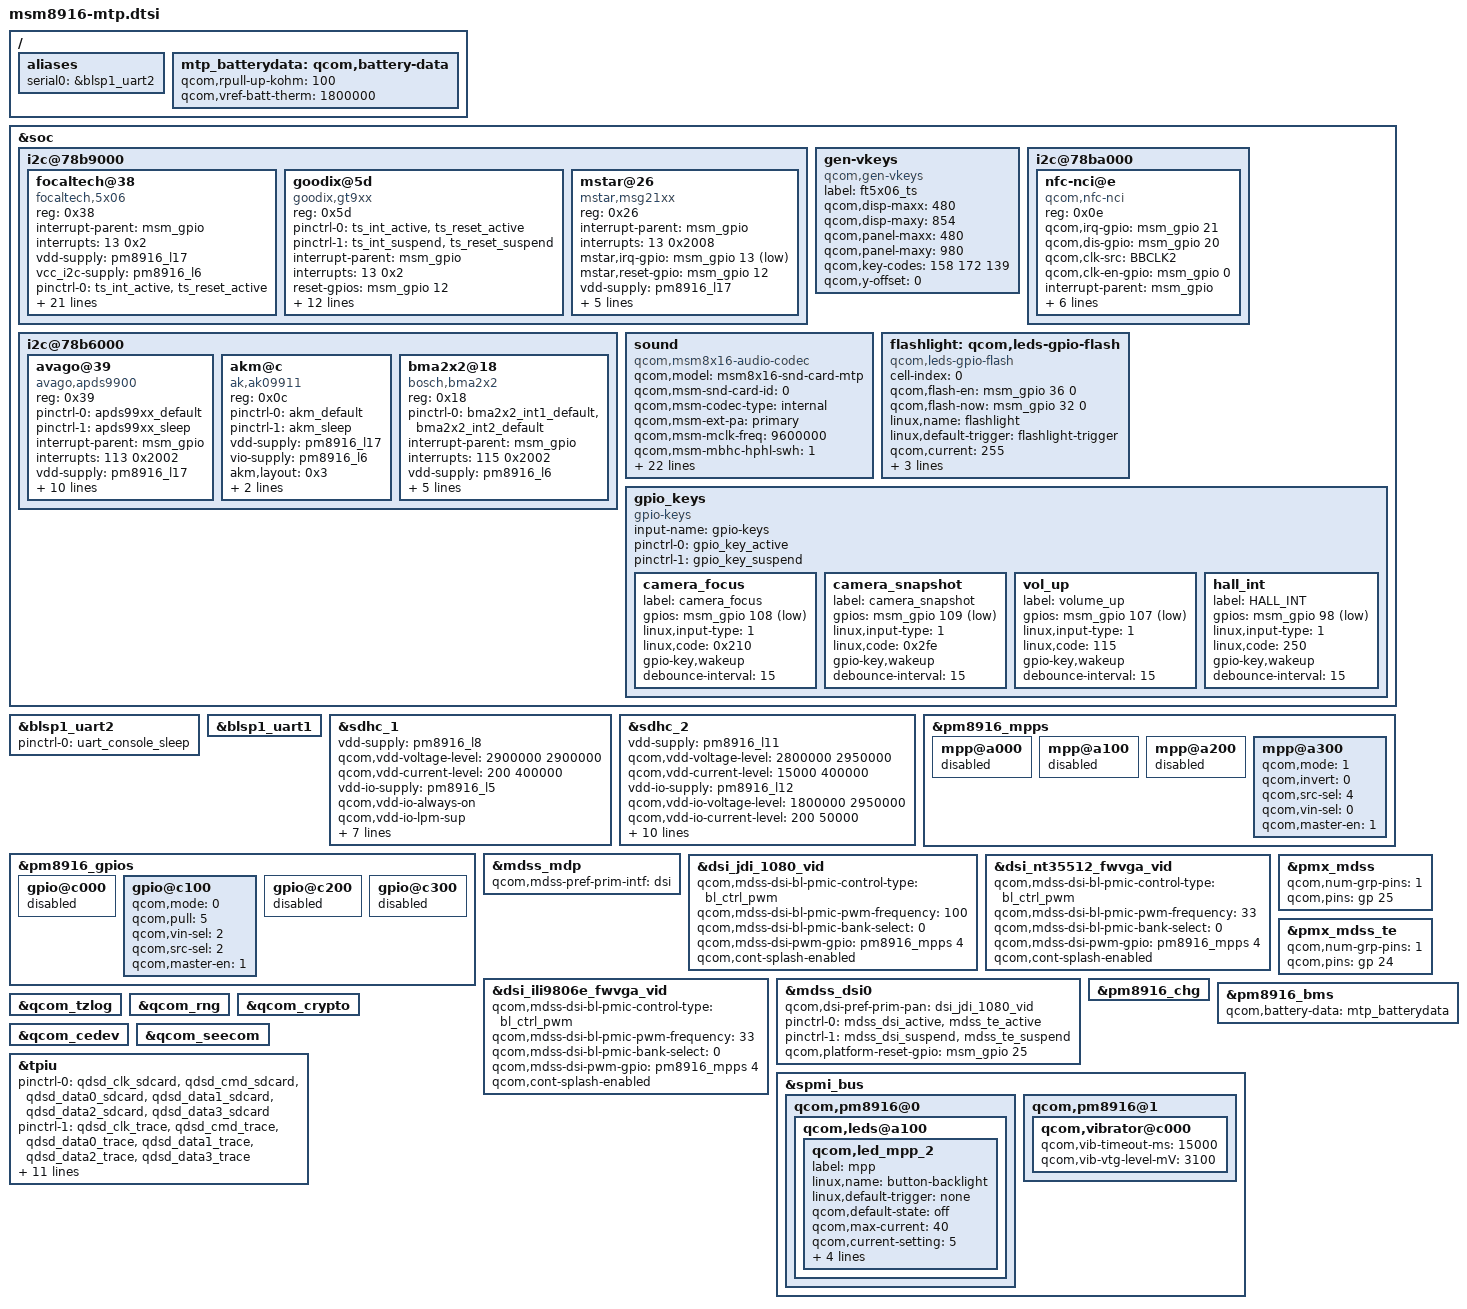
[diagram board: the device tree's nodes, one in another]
/* Copyright (c) 2014, The Linux Foundation. All rights reserved.
 *
 * This program is free software; you can redistribute it and/or modify
 * it under the terms of the GNU General Public License version 2 and
 * only version 2 as published by the Free Software Foundation.
 *
 * This program is distributed in the hope that it will be useful,
 * but WITHOUT ANY WARRANTY; without even the implied warranty of
 * MERCHANTABILITY or FITNESS FOR A PARTICULAR PURPOSE.  See the
 * GNU General Public License for more details.
 */

#include "msm8916.dtsi"
#include "msm8916-pinctrl.dtsi"
#include "msm8916-camera-sensor-mtp.dtsi"

/ {
	aliases {
		serial0 = &blsp1_uart2;
	};
};

&soc {

/*[PLATFORM]-MOD BGEIN by TCTNB.YJ, 2014/03/25, add tp driver */
	i2c@78b9000 { /* BLSP1 QUP5 */
		focaltech@38{
			compatible = "focaltech,5x06";
			reg = <0x38>;
			interrupt-parent = <&msm_gpio>;
			interrupts = <13 0x2>;
			vdd-supply = <&pm8916_l17>;
			vcc_i2c-supply = <&pm8916_l6>;
			/* pins used by touchscreen */
			pinctrl-names = "pmx_ts_active","pmx_ts_suspend";
			pinctrl-0 = <&ts_int_active &ts_reset_active>;
			pinctrl-1 = <&ts_int_suspend &ts_reset_suspend>;
			focaltech,name = "ft6x06";
			focaltech,family-id = <0x06>;
			focaltech,reset-gpio = <&msm_gpio 12 0x00>;
			focaltech,irq-gpio = <&msm_gpio 13 0x00>;
			focaltech,display-coords = <0 0 480 854>;
			focaltech,panel-coords = <0 0 480 980>;
			focaltech,button-map= <139 102 158>;
			focaltech,no-force-update;
			focaltech,i2c-pull-up;
			focaltech,group-id = <1>;
			focaltech,hard-reset-delay-ms = <20>;
			focaltech,soft-reset-delay-ms = <150>;
			focaltech,num-max-touches = <2>;
//                      focaltech,fw-name = "ft_8610_qrd_fw.bin";
			focaltech,fw-delay-aa-ms = <100>;
			focaltech,fw-delay-55-ms = <30>;
			focaltech,fw-upgrade-id1 = <0x79>;
			focaltech,fw-upgrade-id2 = <0x08>;
			focaltech,fw-delay-readid-ms = <10>;
			focaltech,fw-delay-era-flsh-ms = <2000>;
//                      focaltech,fw-auto-cal;
			focaltech,ignore-id-check;
		};
               goodix@5d {
                       compatible = "goodix,gt9xx";
                       reg = <0x5d>;
			/* pins used by touchscreen */
			pinctrl-names = "pmx_ts_active","pmx_ts_suspend";
			pinctrl-0 = <&ts_int_active &ts_reset_active>;
			pinctrl-1 = <&ts_int_suspend &ts_reset_suspend>;

			interrupt-parent = <&msm_gpio>;
			interrupts = <13 0x2>;
			reset-gpios = <&msm_gpio 12 0x00>;
			interrupt-gpios = <&msm_gpio 13 0x00>;

			vdd-supply = <&pm8916_l17>;
			vcc_i2c-supply = <&pm8916_l6>;

			goodix,panel-coords = <0 0 480 854>;
			goodix,display-coords = <0 0 480 980>;
			goodix,button-map= <158 172 139>;
			goodix,product-id = "950";
			goodix,force-update;
			goodix,enable-power-off;
/*                      goodix,cfg-data0 = [
                                46 1C 02 C0 03 0A 05 11 01 08
                                14 3B 46 32 03 05 00 00 00 00
                                00 00 00 00 00 00 00 8A 09 0B
                                39 00 99 0A 00 00 02 83 03 1D
                                00 08 00 00 00 00 00 00 00 00
                                00 1D 73 94 C5 02 07 00 00 04
                                78 21 00 5C 2C 00 48 3A 00 3A
                                4C 00 2F 65 00 30 10 30 50 00
                                56 45 35 FF FF 17 00 00 00 00
                                00 01 1C 15 0C 14 5F 03 02 00
                                00 00 00 00 00 00 00 00 00 00
                                00 00 16 14 12 10 0E 0C 0A 08
                                06 04 02 FF FF FF 00 00 00 00
                                00 00 00 00 00 00 00 00 00 00
                                00 00 22 21 20 1F 1E 1D 1C 18
                                16 12 10 0F 0C 0A 08 06 04 02
                                00 FF FF FF FF FF FF FF 00 00
                                00 FF FF FF FF FF FF FF FF FF
                                F8 FF FF FF E4 01];
*/
//                      goodix,have-touch-key;
			goodix,driver-send-cfg;
			/* Underlying clocks used by secure touch */
			clocks = <&clock_gcc clk_gcc_blsp1_ahb_clk>,
			 <&clock_gcc clk_gcc_blsp1_qup5_i2c_apps_clk>;
			clock-names = "iface_clk", "core_clk";
		};
               mstar@26 {
                       compatible = "mstar,msg21xx";
                       reg = <0x26>;
                       interrupt-parent = <&msm_gpio>;
                       interrupts = <13 0x2008>;
                       mstar,irq-gpio = <&msm_gpio 13 0x00000001>;
                       mstar,reset-gpio = <&msm_gpio 12 0x0>;
                       vdd-supply = <&pm8916_l17>;
                       vcc_i2c-supply = <&pm8916_l6>;
                       mstar,display-coords = <0 0 480 854>;
                       pinctrl-names = "pmx_ts_active","pmx_ts_suspend";
                       pinctrl-0 = <&ts_int_active &ts_reset_active>;
                       pinctrl-1 = <&ts_int_suspend &ts_reset_suspend>;
                       mstar,button-map= <139 172 158>;
               };
	};

	gen-vkeys {
		compatible = "qcom,gen-vkeys";
		label = "ft5x06_ts";
		qcom,disp-maxx = <480>;
		qcom,disp-maxy = <854>;
		qcom,panel-maxx = <480>;
		qcom,panel-maxy = <980>;
		qcom,key-codes = <158 172 139>;
		qcom,y-offset = <0>;
	};
/*[PLATFORM]-END by TCTNB.YJ*/

	i2c@78ba000 { /* BLSP1 QUP6 */
		nfc-nci@e {
			compatible = "qcom,nfc-nci";
			reg = <0x0e>;
			qcom,irq-gpio = <&msm_gpio 21 0x00>;
			qcom,dis-gpio = <&msm_gpio 20 0x00>;
			qcom,clk-src = "BBCLK2";
			qcom,clk-en-gpio = <&msm_gpio 0 0x00>;
			interrupt-parent = <&msm_gpio>;
			interrupts = <21 0>;
			interrupt-names = "nfc_irq";
			pinctrl-names = "nfc_active","nfc_suspend";
			pinctrl-0 = <&nfc_int_active &nfc_disable_active>;
			pinctrl-1 = <&nfc_int_suspend &nfc_disable_suspend>;
			qcom,clk-gpio = <&pm8916_gpios 2 0>;
			clocks = <&clock_rpm clk_bb_clk2_pin>;
			clock-names = "ref_clk";
		};
	};

	i2c@78b6000 { /* BLSP1 QUP2 */
/*[PLATFORM]-Mod-BGEIN by TCTNB.XQJ,2014/08/014, bug 758901,758937 add sensors */
	avago@39 { /* Ambient light and proximity sensor */
		compatible = "avago,apds9900";
		reg = <0x39>;
		pinctrl-names = "default","sleep";
		pinctrl-0 = <&apds99xx_default>;
		pinctrl-1 = <&apds99xx_sleep>;
		interrupt-parent = <&msm_gpio>;
		interrupts = <113 0x2002>;
		vdd-supply = <&pm8916_l17>;
		vio-supply = <&pm8916_l6>;
		avago,irq-gpio = <&msm_gpio 113 0x2002>;
		avago,ps-threshold = <600>;
		avago,ps-hysteresis-threshold = <500>;
		avago,ps-pulse = <20>;
		avago,ps-pgain = <4>;
		avago,als-B = <223>;
		avago,als-C = <70>;
		avago,als-D = <142>;
		avago,ga-value = <48>;
	};

	akm@c {
		compatible = "ak,ak09911";
		reg = <0x0c>;
		pinctrl-names = "default","sleep";
		pinctrl-0 = <&akm_default>;
		pinctrl-1 = <&akm_sleep>;
		vdd-supply = <&pm8916_l17>;
		vio-supply = <&pm8916_l6>;
		akm,layout = <0x3>;
		akm,gpio_rstn = <&msm_gpio 8 0x0>;
		akm,auto-report;
	};

	bma2x2@18 { /* Accelerometer sensor */
		compatible = "bosch,bma2x2";
		reg = <0x18>;
		pinctrl-names = "default";
		pinctrl-0 = <&bma2x2_int1_default &bma2x2_int2_default>;
		interrupt-parent = <&msm_gpio>;
		interrupts = <115 0x2002>;
		vdd-supply = <&pm8916_l6>;
		vio-supply = <&pm8916_l6>;
		bosch,init-interval = <200>;
		bosch,place = <2>;
		bosch,gpio-int1 = <&msm_gpio 115 0x2002>;
		bosch,gpio-int2 = <&msm_gpio 114 0x2002>;
	};

};
/*[PLATFORM]-End by TCTNB.XQJ*/
	sound {
		compatible = "qcom,msm8x16-audio-codec";
		qcom,model = "msm8x16-snd-card-mtp";
		qcom,msm-snd-card-id = <0>;
		qcom,msm-codec-type = "internal";
		qcom,msm-ext-pa = "primary";
		qcom,msm-mclk-freq = <9600000>;
/* [PLATFORM]-Mod-BEGIN by TCTNB.THW, 2014/08/21*/
		qcom,msm-mbhc-hphl-swh = <1>;
/* [PLATFORM]-Mod-END by TCTNB.THW, 2014/08/21*/
		qcom,msm-mbhc-gnd-swh = <0>;
		qcom,msm-micbias1-ext-cap;
		qcom,msm-hs-micbias-type = "internal";
		qcom,audio-routing =
			"RX_BIAS", "MCLK",
			"SPK_RX_BIAS", "MCLK",
			"INT_LDO_H", "MCLK",
/* [PLATFORM]-Mod-BEGIN by TCTNB.THW, 2014/08/21*/
			"MIC BIAS Internal1", "Handset Mic",
			"MIC BIAS Internal2", "Headset Mic",
			"MIC BIAS Internal3", "Secondary Mic",
			"AMIC1", "MIC BIAS Internal1",
			"AMIC2", "MIC BIAS Internal2",
			"AMIC3", "MIC BIAS Internal3",
/* [PLATFORM]-Mod-END by TCTNB.THW, 2014/08/21*/
			"DMIC1", "MIC BIAS Internal1",
			"MIC BIAS Internal1", "Digital Mic1",
			"DMIC2", "MIC BIAS Internal1",
			"MIC BIAS Internal1", "Digital Mic2";
		pinctrl-names = "cdc_lines_act",
				"cdc_lines_sus",
				"cdc_lines_sus",
				"cdc_lines_sec_ext_act",
				"cdc_lines_sec_ext_sus",
				"cross_conn_det_act",
				"cross_conn_det_sus";
		pinctrl-0 = <&cdc_pdm_lines_act>;
		pinctrl-1 = <&cdc_pdm_lines_sus>;
		pinctrl-2 = <&cdc_pdm_lines_act &cdc_ext_pa_act
						&cdc_ext_pa_ws_act>;
		pinctrl-3 = <&cdc_pdm_lines_sus &cdc_ext_pa_sus
						&cdc_ext_pa_ws_sus>;
		pinctrl-4 = <&cross_conn_det_act>;
		pinctrl-5 = <&cross_conn_det_sus>;
/* [PLATFORM]-Mod-BEGIN by TCTNB.THW, 2014/08/21*/
		//qcom,cdc-us-euro-gpios = <&msm_gpio 120 0>;
/* [PLATFORM]-Mod-END by TCTNB.THW, 2014/08/21*/
	};
};

&blsp1_uart2 {
	status = "ok";
	pinctrl-names = "default";
	pinctrl-0 = <&uart_console_sleep>;
};

&soc {

	flashlight: qcom,leds-gpio-flash{
		cell-index = <0>;
		compatible = "qcom,leds-gpio-flash";
		status = "okay";
		qcom,flash-en = <&msm_gpio 36 0>;
		qcom,flash-now = <&msm_gpio 32 0>;
		linux,name = "flashlight";
		linux,default-trigger = "flashlight-trigger";
		qcom,current = <255>;
/* [PLATFORM]-Add-BEGIN by TCTNB.qijiang.yu, 2014/05/13, flash enable use gp_clk */
		clocks = <&clock_gcc clk_gcc_camss_gp1_clk>;
		clock-names = "cam_sensor_flash";

		pinctrl-names = "default", "sleep";
/*
		pinctrl-0 = <&ice40_infrared_default>;
		pinctrl-1 = <&ice40_infrared_sleep>;
*/
		pinctrl-0 = <&cam_sensor_flash_default>;
		pinctrl-1 = <&cam_sensor_flash_sleep>;
/* [PLATFORM]-Add-END by TCTNB.qijiang.yu */
	};
/* [PLATFORM]-Add-END by TCTNB.Alvin */
	gpio_keys {
		compatible = "gpio-keys";
		input-name = "gpio-keys";
		pinctrl-names = "tlmm_gpio_key_active","tlmm_gpio_key_suspend";
		pinctrl-0 = <&gpio_key_active>;
		pinctrl-1 = <&gpio_key_suspend>;

		camera_focus {
			label = "camera_focus";
			gpios = <&msm_gpio 108 0x1>;
			linux,input-type = <1>;
			linux,code = <0x210>;
			gpio-key,wakeup;
			debounce-interval = <15>;
		};

		camera_snapshot {
			label = "camera_snapshot";
			gpios = <&msm_gpio 109 0x1>;
			linux,input-type = <1>;
			linux,code = <0x2fe>;
			gpio-key,wakeup;
			debounce-interval = <15>;
		};

		vol_up {
			label = "volume_up";
			gpios = <&msm_gpio 107 0x1>;
			linux,input-type = <1>;
			linux,code = <115>;
			gpio-key,wakeup;
			debounce-interval = <15>;
		};
		/* [PLATFORM]-ADD-BEGIN by ning.wei SZ for HALL driver 2014-07-25 */
		hall_int {
			label = "HALL_INT";
			gpios = <&msm_gpio 98 0x1>;
			linux,input-type = <1>;
			linux,code = <250>;
			gpio-key,wakeup;
			debounce-interval = <15>;
		};
		/* [PLATFORM]-ADD-END by ning.wei SZ */
	};
};

&blsp1_uart1 {
	status = "ok";
};

&sdhc_1 {
	vdd-supply = <&pm8916_l8>;
	qcom,vdd-voltage-level = <2900000 2900000>;
	qcom,vdd-current-level = <200 400000>;

	vdd-io-supply = <&pm8916_l5>;
	qcom,vdd-io-always-on;
	qcom,vdd-io-lpm-sup;
	qcom,vdd-io-voltage-level = <1800000 1800000>;
	qcom,vdd-io-current-level = <200 60000>;

	pinctrl-names = "active", "sleep";
	pinctrl-0 = <&sdc1_clk_on &sdc1_cmd_on &sdc1_data_on>;
	pinctrl-1 = <&sdc1_clk_off &sdc1_cmd_off &sdc1_data_off>;

	qcom,nonremovable;

	status = "ok";
};

&sdhc_2 {
	vdd-supply = <&pm8916_l11>;
	qcom,vdd-voltage-level = <2800000 2950000>;
	qcom,vdd-current-level = <15000 400000>;

	vdd-io-supply = <&pm8916_l12>;
	qcom,vdd-io-voltage-level = <1800000 2950000>;
	qcom,vdd-io-current-level = <200 50000>;

	pinctrl-names = "active", "sleep";
	pinctrl-0 = <&sdc2_clk_on &sdc2_cmd_on &sdc2_data_on &sdc2_cd_on>;
	pinctrl-1 = <&sdc2_clk_off &sdc2_cmd_off &sdc2_data_off &sdc2_cd_off>;

	#address-cells = <0>;
	interrupt-parent = <&sdhc_2>;
	interrupts = <0 1 2>;
	#interrupt-cells = <1>;
	interrupt-map-mask = <0xffffffff>;
	interrupt-map = <0 &intc 0 125 0
			1 &intc 0 221 0
			2 &msm_gpio 38 0>;
	interrupt-names = "hc_irq", "pwr_irq", "status_irq";
	cd-gpios = <&msm_gpio 38 0x1>;

	status = "ok";
};

&pm8916_mpps {
	mpp@a000 { /* MPP 1 */
		/* VDD_PX */
		status = "disabled";
	};

	mpp@a100 { /* MPP 2 */
		/* HR LED */
		status = "disabled";
	};

	mpp@a200 { /* MPP 3 */
		/* VREF DAC */
		status = "disabled";
	};

	mpp@a300 { /* MPP 4 */
		/* Backlight PWM */
		qcom,mode = <1>;		/* Digital output */
		qcom,invert = <0>;		/* Disable invert */
		qcom,src-sel = <4>;		/* DTEST1 */
		qcom,vin-sel = <0>;		/* VPH_PWR */
		qcom,master-en = <1>;		/* Enable MPP */
	};
};

&pm8916_gpios {
	gpio@c000 { /* GPIO 1 */
		/* Battery UICC Alarm */
		status = "disabled";
	};

	gpio@c100 { /* GPIO 2 */
		/* NFC_CLK_REQ */
		qcom,mode = <0>; /* QPNP_PIN_MODE_DIG_IN */
		qcom,pull = <5>; /* QPNP_PIN_PULL_NO */
		qcom,vin-sel = <2>; /* QPNP_PIN_VIN2 */
		qcom,src-sel = <2>; /* QPNP_PIN_SEL_FUNC_1 */
		qcom,master-en = <1>;
	};

	gpio@c200 { /* GPIO 3 */
		/* External regulator control for WTR */
		status = "disabled";
	};

	gpio@c300 { /* GPIO 4 */
		/* External regulator control for APC */
		status = "disabled";
	};
};

#include "dsi-panel-jdi-1080p-video.dtsi"

&mdss_mdp {
	qcom,mdss-pref-prim-intf = "dsi";
};

&dsi_jdi_1080_vid {
	qcom,mdss-dsi-bl-pmic-control-type = "bl_ctrl_pwm";
	qcom,mdss-dsi-bl-pmic-pwm-frequency = <100>;
	qcom,mdss-dsi-bl-pmic-bank-select = <0>;
	qcom,mdss-dsi-pwm-gpio = <&pm8916_mpps 4 0>;

};
/* [PLATFORM]-Add-BEGIN by TCTNB.ZXZ, FR-747792, 2014/07/21, Add ili9806e for Alto4.5 LATAM 2st lcd */
&dsi_nt35512_fwvga_vid {
/* [PLATFORM]-Add-END by TCTNB.FLF */
       qcom,mdss-dsi-bl-pmic-control-type = "bl_ctrl_pwm";
       /*qcom,mdss-dsi-bl-pmic-pwm-frequency = <100>;*/
       qcom,mdss-dsi-bl-pmic-pwm-frequency = <33>;
       qcom,mdss-dsi-bl-pmic-bank-select = <0>;
       qcom,mdss-dsi-pwm-gpio = <&pm8916_mpps 4 0>;
       qcom,cont-splash-enabled;
};

&dsi_ili9806e_fwvga_vid {
       qcom,mdss-dsi-bl-pmic-control-type = "bl_ctrl_pwm";
       qcom,mdss-dsi-bl-pmic-pwm-frequency = <33>;
       qcom,mdss-dsi-bl-pmic-bank-select = <0>;
       qcom,mdss-dsi-pwm-gpio = <&pm8916_mpps 4 0>;
       qcom,cont-splash-enabled;
};
/* [PLATFORM]-Add-END by TCTNB.ZXZ*/


&pmx_mdss {
	qcom,num-grp-pins = <1>;
	qcom,pins =  <&gp 25>;/*remove gpio cfg not used by lcd*/
};

&pmx_mdss_te {
	qcom,num-grp-pins = <1>;
	qcom,pins = <&gp 24>;
};

&mdss_dsi0 {
	qcom,dsi-pref-prim-pan = <&dsi_jdi_1080_vid>;
	pinctrl-names = "mdss_default", "mdss_sleep";
	pinctrl-0 = <&mdss_dsi_active &mdss_te_active>;
	pinctrl-1 = <&mdss_dsi_suspend &mdss_te_suspend>;

//	qcom,platform-enable-gpio = <&msm_gpio 97 0>;/*remove gpio cfg not used by lcd*/
	qcom,platform-reset-gpio = <&msm_gpio 25 0>;
//	qcom,platform-bklight-en-gpio = <&msm_gpio 98 0>;/*remove gpio cfg not used by lcd*/
};

&dsi_jdi_1080_vid {
       qcom,cont-splash-enabled;
};

&pm8916_chg {
	status = "ok";
//	qcom,charging-disabled;
};

/ {
	mtp_batterydata: qcom,battery-data {
		qcom,rpull-up-kohm = <100>;
		qcom,vref-batt-therm = <1800000>;

/* [PLATFORM]-Add-BEGIN by TCTNB.FLF, PR-831921, 2014/11/10, add battery profile for alto4_latam */
//		#include "batterydata-palladium.dtsi"
		#include "TCL_TLi020F1BYD_1600928_2000mAh_VBMS_3p4COV_Final.dtsi"
		#include "TCL_TLi020F2SCUD_1600878_2000mAh_3p4COV_VBMS_Final.dtsi"
/* [PLATFORM]-Add-END by TCTNB.FLF */
	};
};

&pm8916_bms {
	status = "ok";
	qcom,battery-data = <&mtp_batterydata>;
};

&spmi_bus {
	qcom,pm8916@0 {
		qcom,leds@a100 {
			status = "okay";
			qcom,led_mpp_2 {
				label = "mpp";
				linux,name = "button-backlight";
				linux,default-trigger = "none";
				qcom,default-state = "off";
				qcom,max-current = <40>;
				qcom,current-setting = <5>;
				qcom,id = <6>;
				qcom,mode = "manual";
				qcom,source-sel = <1>;
				qcom,mode-ctrl = <0x60>;
			};
		};
	};
};

&qcom_tzlog {
	status = "okay";
};

&qcom_rng {
	status = "okay";
};

&qcom_crypto {
	status = "okay";
};

&qcom_cedev {
	status = "okay";
};

&qcom_seecom {
	status = "okay";
};

/* CoreSight */
&tpiu {
      pinctrl-names = "sdcard", "trace", "swduart",
		      "swdtrc", "jtag", "spmi";
       /* NIDnT */
      pinctrl-0 = <&qdsd_clk_sdcard &qdsd_cmd_sdcard
                  &qdsd_data0_sdcard &qdsd_data1_sdcard
                  &qdsd_data2_sdcard &qdsd_data3_sdcard>;
      pinctrl-1 = <&qdsd_clk_trace &qdsd_cmd_trace
                  &qdsd_data0_trace &qdsd_data1_trace
                  &qdsd_data2_trace &qdsd_data3_trace>;
      pinctrl-2 = <&qdsd_cmd_swduart &qdsd_data0_swduart
                  &qdsd_data1_swduart &qdsd_data2_swduart
                  &qdsd_data3_swduart>;
      pinctrl-3 = <&qdsd_clk_swdtrc &qdsd_cmd_swdtrc
                  &qdsd_data0_swdtrc &qdsd_data1_swdtrc
                  &qdsd_data2_swdtrc &qdsd_data3_swdtrc>;
      pinctrl-4 = <&qdsd_cmd_jtag &qdsd_data0_jtag
                  &qdsd_data1_jtag &qdsd_data2_jtag
                  &qdsd_data3_jtag>;
      pinctrl-5 = <&qdsd_clk_spmi &qdsd_cmd_spmi
                  &qdsd_data0_spmi &qdsd_data3_spmi>;
};

&spmi_bus {
	qcom,pm8916@1 {
		qcom,vibrator@c000 {
			status = "okay";
			qcom,vib-timeout-ms = <15000>;
			qcom,vib-vtg-level-mV = <3100>;
		};
	};
};
